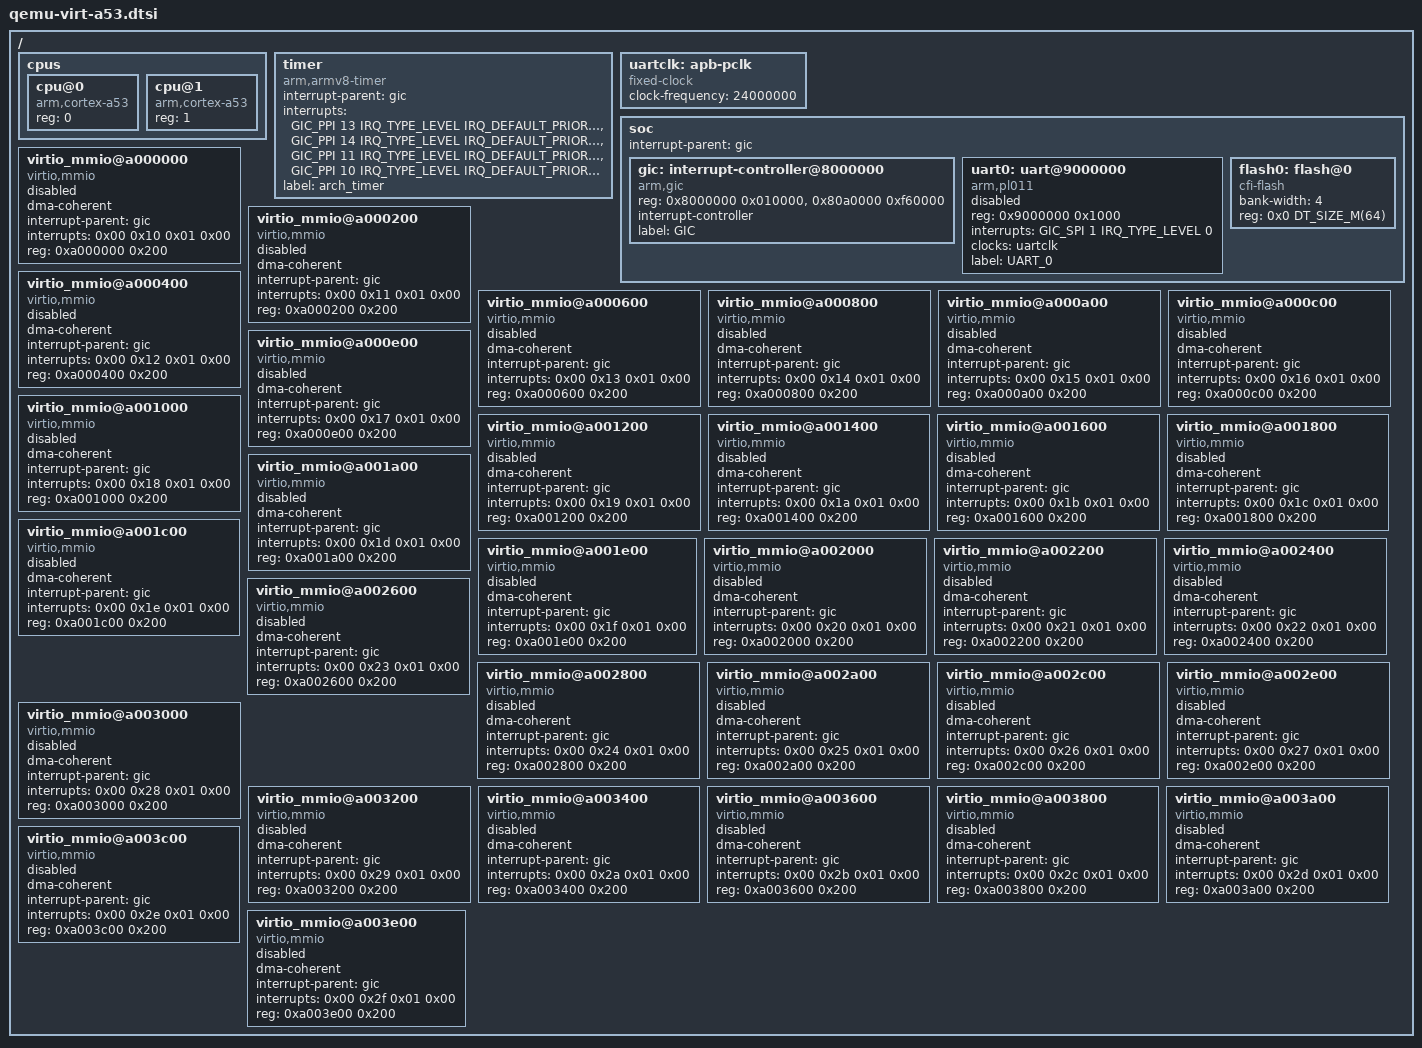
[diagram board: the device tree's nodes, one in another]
/*
 * Copyright (c) 2019 Carlo Caione <ccaione@baylibre.com>
 *
 * SPDX-License-Identifier: Apache-2.0
 */

/*
 * Derived from DTS extracted with:
 *
 *   qemu-system-aarch64 -machine virt -cpu cortex-a53 -nographic
 *         -machine dumpdtb=virt.dtb
 *
 *   dtc -I dtb -O dts virt.dtb
 */

#include <mem.h>
#include <arm64/armv8-a.dtsi>
#include <dt-bindings/interrupt-controller/arm-gic.h>

/ {
	cpus {
		#address-cells = <1>;
		#size-cells = <0>;

		cpu@0 {
			device_type = "cpu";
			compatible = "arm,cortex-a53";
			reg = <0>;
		};

		cpu@1 {
			device_type = "cpu";
			compatible = "arm,cortex-a53";
			reg = <1>;
		};
	};

	timer {
		compatible = "arm,armv8-timer";
		interrupt-parent = <&gic>;
		interrupts = <GIC_PPI 13 IRQ_TYPE_LEVEL
			      IRQ_DEFAULT_PRIORITY>,
			     <GIC_PPI 14 IRQ_TYPE_LEVEL
			      IRQ_DEFAULT_PRIORITY>,
			     <GIC_PPI 11 IRQ_TYPE_LEVEL
			      IRQ_DEFAULT_PRIORITY>,
			     <GIC_PPI 10 IRQ_TYPE_LEVEL
			      IRQ_DEFAULT_PRIORITY>;
		label = "arch_timer";
	};

	uartclk: apb-pclk {
		compatible = "fixed-clock";
		clock-frequency = <24000000>;
		#clock-cells = <0>;
	};

	soc {
		interrupt-parent = <&gic>;

		gic: interrupt-controller@8000000 {
			compatible = "arm,gic";
			reg = <0x8000000 0x010000>,
			      <0x80a0000 0xf60000>;
			interrupt-controller;
			#interrupt-cells = <4>;
			label = "GIC";
			status = "okay";
		};

		uart0: uart@9000000 {
			compatible = "arm,pl011";
			reg = <0x9000000 0x1000>;
			status = "disabled";
			interrupts = <GIC_SPI 1 IRQ_TYPE_LEVEL 0>;
			interrupt-names = "irq_0";
			clocks = <&uartclk>;
			label = "UART_0";
		};

		flash0: flash@0 {
			compatible = "cfi-flash";
			bank-width = <4>;
			/* As this is pointed to by zephyr,flash we can only handle
			 * one value in the reg property, so we comment out the
			 * second flash bank for now
			 */
			reg = <0x0 DT_SIZE_M(64) /* 0x4000000 DT_SIZE_M(64) */>;
		};
	};

	virtio_mmio@a000000 {
		dma-coherent;
		interrupt-parent = <&gic>;
		interrupts = <0x00 0x10 0x01 0x00>;
		reg = <0xa000000 0x200>;
		compatible = "virtio,mmio";
		status = "disabled";
	};

	virtio_mmio@a000200 {
		dma-coherent;
		interrupt-parent = <&gic>;
		interrupts = <0x00 0x11 0x01 0x00>;
		reg = <0xa000200 0x200>;
		compatible = "virtio,mmio";
		status = "disabled";
	};

	virtio_mmio@a000400 {
		dma-coherent;
		interrupt-parent = <&gic>;
		interrupts = <0x00 0x12 0x01 0x00>;
		reg = <0xa000400 0x200>;
		compatible = "virtio,mmio";
		status = "disabled";
	};

	virtio_mmio@a000600 {
		dma-coherent;
		interrupt-parent = <&gic>;
		interrupts = <0x00 0x13 0x01 0x00>;
		reg = <0xa000600 0x200>;
		compatible = "virtio,mmio";
		status = "disabled";
	};

	virtio_mmio@a000800 {
		dma-coherent;
		interrupt-parent = <&gic>;
		interrupts = <0x00 0x14 0x01 0x00>;
		reg = <0xa000800 0x200>;
		compatible = "virtio,mmio";
		status = "disabled";
	};

	virtio_mmio@a000a00 {
		dma-coherent;
		interrupt-parent = <&gic>;
		interrupts = <0x00 0x15 0x01 0x00>;
		reg = <0xa000a00 0x200>;
		compatible = "virtio,mmio";
		status = "disabled";
	};

	virtio_mmio@a000c00 {
		dma-coherent;
		interrupt-parent = <&gic>;
		interrupts = <0x00 0x16 0x01 0x00>;
		reg = <0xa000c00 0x200>;
		compatible = "virtio,mmio";
		status = "disabled";
	};

	virtio_mmio@a000e00 {
		dma-coherent;
		interrupt-parent = <&gic>;
		interrupts = <0x00 0x17 0x01 0x00>;
		reg = <0xa000e00 0x200>;
		compatible = "virtio,mmio";
		status = "disabled";
	};

	virtio_mmio@a001000 {
		dma-coherent;
		interrupt-parent = <&gic>;
		interrupts = <0x00 0x18 0x01 0x00>;
		reg = <0xa001000 0x200>;
		compatible = "virtio,mmio";
		status = "disabled";
	};

	virtio_mmio@a001200 {
		dma-coherent;
		interrupt-parent = <&gic>;
		interrupts = <0x00 0x19 0x01 0x00>;
		reg = <0xa001200 0x200>;
		compatible = "virtio,mmio";
		status = "disabled";
	};

	virtio_mmio@a001400 {
		dma-coherent;
		interrupt-parent = <&gic>;
		interrupts = <0x00 0x1a 0x01 0x00>;
		reg = <0xa001400 0x200>;
		compatible = "virtio,mmio";
		status = "disabled";
	};

	virtio_mmio@a001600 {
		dma-coherent;
		interrupt-parent = <&gic>;
		interrupts = <0x00 0x1b 0x01 0x00>;
		reg = <0xa001600 0x200>;
		compatible = "virtio,mmio";
		status = "disabled";
	};

	virtio_mmio@a001800 {
		dma-coherent;
		interrupt-parent = <&gic>;
		interrupts = <0x00 0x1c 0x01 0x00>;
		reg = <0xa001800 0x200>;
		compatible = "virtio,mmio";
		status = "disabled";
	};

	virtio_mmio@a001a00 {
		dma-coherent;
		interrupt-parent = <&gic>;
		interrupts = <0x00 0x1d 0x01 0x00>;
		reg = <0xa001a00 0x200>;
		compatible = "virtio,mmio";
		status = "disabled";
	};

	virtio_mmio@a001c00 {
		dma-coherent;
		interrupt-parent = <&gic>;
		interrupts = <0x00 0x1e 0x01 0x00>;
		reg = <0xa001c00 0x200>;
		compatible = "virtio,mmio";
		status = "disabled";
	};

	virtio_mmio@a001e00 {
		dma-coherent;
		interrupt-parent = <&gic>;
		interrupts = <0x00 0x1f 0x01 0x00>;
		reg = <0xa001e00 0x200>;
		compatible = "virtio,mmio";
		status = "disabled";
	};

	virtio_mmio@a002000 {
		dma-coherent;
		interrupt-parent = <&gic>;
		interrupts = <0x00 0x20 0x01 0x00>;
		reg = <0xa002000 0x200>;
		compatible = "virtio,mmio";
		status = "disabled";
	};

	virtio_mmio@a002200 {
		dma-coherent;
		interrupt-parent = <&gic>;
		interrupts = <0x00 0x21 0x01 0x00>;
		reg = <0xa002200 0x200>;
		compatible = "virtio,mmio";
		status = "disabled";
	};

	virtio_mmio@a002400 {
		dma-coherent;
		interrupt-parent = <&gic>;
		interrupts = <0x00 0x22 0x01 0x00>;
		reg = <0xa002400 0x200>;
		compatible = "virtio,mmio";
		status = "disabled";
	};

	virtio_mmio@a002600 {
		dma-coherent;
		interrupt-parent = <&gic>;
		interrupts = <0x00 0x23 0x01 0x00>;
		reg = <0xa002600 0x200>;
		compatible = "virtio,mmio";
		status = "disabled";
	};

	virtio_mmio@a002800 {
		dma-coherent;
		interrupt-parent = <&gic>;
		interrupts = <0x00 0x24 0x01 0x00>;
		reg = <0xa002800 0x200>;
		compatible = "virtio,mmio";
		status = "disabled";
	};

	virtio_mmio@a002a00 {
		dma-coherent;
		interrupt-parent = <&gic>;
		interrupts = <0x00 0x25 0x01 0x00>;
		reg = <0xa002a00 0x200>;
		compatible = "virtio,mmio";
		status = "disabled";
	};

	virtio_mmio@a002c00 {
		dma-coherent;
		interrupt-parent = <&gic>;
		interrupts = <0x00 0x26 0x01 0x00>;
		reg = <0xa002c00 0x200>;
		compatible = "virtio,mmio";
		status = "disabled";
	};

	virtio_mmio@a002e00 {
		dma-coherent;
		interrupt-parent = <&gic>;
		interrupts = <0x00 0x27 0x01 0x00>;
		reg = <0xa002e00 0x200>;
		compatible = "virtio,mmio";
		status = "disabled";
	};

	virtio_mmio@a003000 {
		dma-coherent;
		interrupt-parent = <&gic>;
		interrupts = <0x00 0x28 0x01 0x00>;
		reg = <0xa003000 0x200>;
		compatible = "virtio,mmio";
		status = "disabled";
	};

	virtio_mmio@a003200 {
		dma-coherent;
		interrupt-parent = <&gic>;
		interrupts = <0x00 0x29 0x01 0x00>;
		reg = <0xa003200 0x200>;
		compatible = "virtio,mmio";
		status = "disabled";
	};

	virtio_mmio@a003400 {
		dma-coherent;
		interrupt-parent = <&gic>;
		interrupts = <0x00 0x2a 0x01 0x00>;
		reg = <0xa003400 0x200>;
		compatible = "virtio,mmio";
		status = "disabled";
	};

	virtio_mmio@a003600 {
		dma-coherent;
		interrupt-parent = <&gic>;
		interrupts = <0x00 0x2b 0x01 0x00>;
		reg = <0xa003600 0x200>;
		compatible = "virtio,mmio";
		status = "disabled";
	};

	virtio_mmio@a003800 {
		dma-coherent;
		interrupt-parent = <&gic>;
		interrupts = <0x00 0x2c 0x01 0x00>;
		reg = <0xa003800 0x200>;
		compatible = "virtio,mmio";
		status = "disabled";
	};

	virtio_mmio@a003a00 {
		dma-coherent;
		interrupt-parent = <&gic>;
		interrupts = <0x00 0x2d 0x01 0x00>;
		reg = <0xa003a00 0x200>;
		compatible = "virtio,mmio";
		status = "disabled";
	};

	virtio_mmio@a003c00 {
		dma-coherent;
		interrupt-parent = <&gic>;
		interrupts = <0x00 0x2e 0x01 0x00>;
		reg = <0xa003c00 0x200>;
		compatible = "virtio,mmio";
		status = "disabled";
	};

	virtio_mmio@a003e00 {
		dma-coherent;
		interrupt-parent = <&gic>;
		interrupts = <0x00 0x2f 0x01 0x00>;
		reg = <0xa003e00 0x200>;
		compatible = "virtio,mmio";
		status = "disabled";
	};

};
